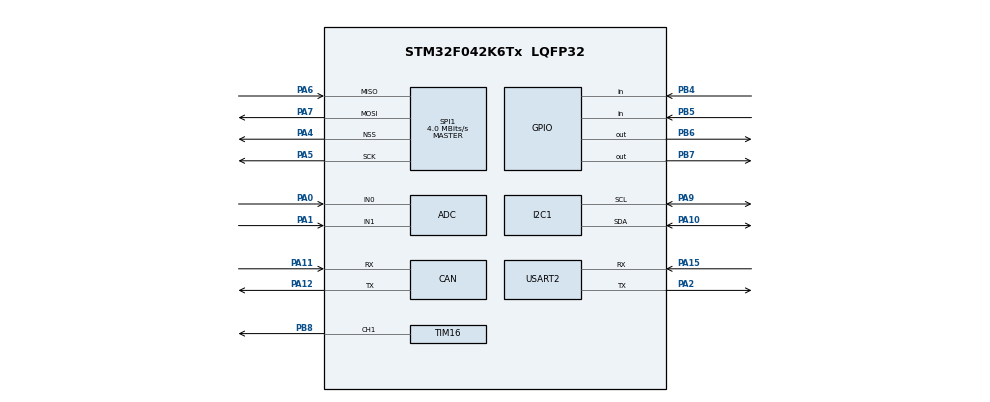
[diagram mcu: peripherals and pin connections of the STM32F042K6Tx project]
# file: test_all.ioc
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CAN.CalculateTimeBit=6000
CAN.CalculateTimeQuantum=2000.0
Mcu.Family=STM32F0
Mcu.Name=STM32F042K6Tx
Mcu.Package=LQFP32
PA0.Mode=IN0
PA0.Signal=ADC_IN0
PA1.Mode=IN1
PA1.Signal=ADC_IN1
PA10.Mode=I2C
PA10.Signal=I2C1_SDA
PA11.Mode=Master
PA11.Signal=CAN_RX
PA12.Mode=Master
PA12.Signal=CAN_TX
PA15.Mode=Asynchronous
PA15.Signal=USART2_RX
PA2.Mode=Asynchronous
PA2.Signal=USART2_TX
PA4.Mode=NSS_Signal_Hard_Output
PA4.Signal=SPI1_NSS
PA5.Mode=Full_Duplex_Master
PA5.Signal=SPI1_SCK
PA6.Mode=Full_Duplex_Master
PA6.Signal=SPI1_MISO
PA7.Mode=Full_Duplex_Master
PA7.Signal=SPI1_MOSI
PA9.Mode=I2C
PA9.Signal=I2C1_SCL
PB4.Signal=GPIO_Input
PB5.Signal=GPIO_Input
PB6.Signal=GPIO_Output
PB7.Signal=GPIO_Output
PB8.Signal=S_TIM16_CH1
ProjectManager.HeapSize=0x200
ProjectManager.StackSize=0x400
ProjectManager.TargetToolchain=Makefile
SH.S_TIM16_CH1.0=TIM16_CH1,PWM Generation1 CH1
SPI1.CalculateBaudRate=4.0 MBits/s
SPI1.Direction=SPI_DIRECTION_2LINES
SPI1.Mode=SPI_MODE_MASTER
SPI1.VirtualNSS=VM_NSSHARD
SPI1.VirtualType=VM_MASTER
TIM16.Channel=TIM_CHANNEL_1
USART2.VirtualMode-Asynchronous=VM_ASYNC
VP_ADC_TempSens_Input.Mode=IN-TempSens
VP_ADC_Vbat_Input.Mode=IN-Vbat
VP_TIM16_VS_ClockSourceINT.Mode=Enable_Timer
board=test_all

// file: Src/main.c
/**
  ******************************************************************************
  * File Name          : main.c
  * Description        : Main program body
  ******************************************************************************
  ** This notice applies to any and all portions of this file
  * that are not between comment pairs USER CODE BEGIN and
  * USER CODE END. Other portions of this file, whether
  * inserted by the user or by software development tools
  * are owned by their respective copyright owners.
  *
  * COPYRIGHT(c) 2017 STMicroelectronics
  *
  * Redistribution and use in source and binary forms, with or without modification,
  * are permitted provided that the following conditions are met:
  *   1. Redistributions of source code must retain the above copyright notice,
  *      this list of conditions and the following disclaimer.
  *   2. Redistributions in binary form must reproduce the above copyright notice,
  *      this list of conditions and the following disclaimer in the documentation
  *      and/or other materials provided with the distribution.
  *   3. Neither the name of STMicroelectronics nor the names of its contributors
  *      may be used to endorse or promote products derived from this software
  *      without specific prior written permission.
  *
  * THIS SOFTWARE IS PROVIDED BY THE COPYRIGHT HOLDERS AND CONTRIBUTORS "AS IS"
  * AND ANY EXPRESS OR IMPLIED WARRANTIES, INCLUDING, BUT NOT LIMITED TO, THE
  * IMPLIED WARRANTIES OF MERCHANTABILITY AND FITNESS FOR A PARTICULAR PURPOSE ARE
  * DISCLAIMED. IN NO EVENT SHALL THE COPYRIGHT HOLDER OR CONTRIBUTORS BE LIABLE
  * FOR ANY DIRECT, INDIRECT, INCIDENTAL, SPECIAL, EXEMPLARY, OR CONSEQUENTIAL
  * DAMAGES (INCLUDING, BUT NOT LIMITED TO, PROCUREMENT OF SUBSTITUTE GOODS OR
  * SERVICES; LOSS OF USE, DATA, OR PROFITS; OR BUSINESS INTERRUPTION) HOWEVER
  * CAUSED AND ON ANY THEORY OF LIABILITY, WHETHER IN CONTRACT, STRICT LIABILITY,
  * OR TORT (INCLUDING NEGLIGENCE OR OTHERWISE) ARISING IN ANY WAY OUT OF THE USE
  * OF THIS SOFTWARE, EVEN IF ADVISED OF THE POSSIBILITY OF SUCH DAMAGE.
  *
  ******************************************************************************
  */

#include "main.h"
#include "stm32f0xx_hal.h"

ADC_HandleTypeDef hadc;

CAN_HandleTypeDef hcan;

I2C_HandleTypeDef hi2c1;

SPI_HandleTypeDef hspi1;

TIM_HandleTypeDef htim16;

UART_HandleTypeDef huart2;

/* USER CODE BEGIN PV */
/* Private variables ---------------------------------------------------------*/

/* USER CODE END PV */

void SystemClock_Config(void);
static void MX_GPIO_Init(void);
static void MX_CAN_Init(void);
static void MX_I2C1_Init(void);
static void MX_ADC_Init(void);
static void MX_SPI1_Init(void);
static void MX_TIM16_Init(void);
static void MX_USART2_UART_Init(void);

void HAL_TIM_MspPostInit(TIM_HandleTypeDef *htim);

/* USER CODE BEGIN PFP */
/* Private function prototypes -----------------------------------------------*/

/* USER CODE END PFP */

/* USER CODE BEGIN 0 */
uint32_t value;
HAL_StatusTypeDef mystatus;
/* USER CODE END 0 */

int main(void)
{

  /* MCU Configuration----------------------------------------------------------*/

  /* Reset of all peripherals, Initializes the Flash interface and the Systick. */
  HAL_Init();

  /* Configure the system clock */
  SystemClock_Config();

  /* Initialize all configured peripherals */
  MX_GPIO_Init();
  MX_CAN_Init();
  MX_I2C1_Init();
  MX_ADC_Init();
  MX_SPI1_Init();
  MX_TIM16_Init();
  MX_USART2_UART_Init();

  //uint8_t mytxbuf = {0xF0, 0xAA}
  uint8_t mytxbuf[] = {'a', 'b', 'c'};
  uint8_t myi2crxbuf[2];

  HAL_UART_Transmit(&huart2, "HI THERE", 8, 500);
  if(myi2crxbuf == NULL) {
  HAL_UART_Transmit(&huart2, "Null", 4, 500);
   }

  //I2C constants
  uint16_t addr = 0x006BU<<1;
  uint16_t reg = 0x000F;
  while (1) {
    myi2crxbuf[0] = 'n';
    mystatus = HAL_I2C_Mem_Read(&hi2c1, addr, reg, 1, myi2crxbuf, 1, 500);
    if (mystatus == HAL_OK) {
      //Status OK, print out the received data
      HAL_UART_Transmit(&huart2, "Stat OK\n\r", 9, 500);
      HAL_UART_Transmit(&huart2, "Rec: ", 5, 500);
      HAL_UART_Transmit(&huart2, myi2crxbuf, 1, 500);
      HAL_UART_Transmit(&huart2, "\r\n", 2, 500);
      HAL_GPIO_TogglePin(GPIOB, GPIO_PIN_3);
    } else if (mystatus == HAL_ERROR) {
      //Error Status, print out the reason
      uint8_t errcode = hi2c1.ErrorCode + '0';
      HAL_UART_Transmit(&huart2, "ERROR_CODE ", 11, 500);
      HAL_UART_Transmit(&huart2, &errcode, 1, 500);
      HAL_UART_Transmit(&huart2, "\r\n", 2, 500);
    } else if (mystatus == HAL_BUSY) {
      HAL_UART_Transmit(&huart2, "Stat BUS\n\r", 10, 500);
    } else if (mystatus == HAL_TIMEOUT) {
      HAL_UART_Transmit(&huart2, "Stat TIM\n\r", 10, 500);
    } else {
      HAL_UART_Transmit(&huart2, "Stat ???\n\r", 10, 500);
    }

    HAL_Delay(500);
    //Set the ADC to read from specific channels in setup for group mode
    //Then call Start, and poll for conversion.  GetValue into a buffer, and read for as many times as channels setup.
    //Call start for next polling round.

    // Start and wait for the conversion
    /*HAL_ADC_Start(&hadc);
    HAL_ADC_PollForConversion(&hadc, 500); //500 msec timeout
    value = HAL_ADC_GetValue(&hadc);
    if (value > (4096/2)) {
      HAL_GPIO_WritePin(GPIOB, GPIO_PIN_3, GPIO_PIN_SET);
    } else {
      HAL_GPIO_WritePin(GPIOB, GPIO_PIN_3, GPIO_PIN_RESET);
    }*/

  }

  /* Now that everything is setup, start the PWM output */
  // HAL_TIM_Base_Start(&htim16);
  // HAL_TIM_PWM_Start(&htim16, TIM_CHANNEL_1);
  // /* Infinite loop */
  // /* USER CODE BEGIN WHILE */
  // uint8_t toggle = 0;

  // while (1) {
  // /* USER CODE END WHILE */
  //   if (toggle) {
  //     __HAL_TIM_SET_COMPARE(&htim16, TIM_CHANNEL_1, 2000);
  //     HAL_GPIO_WritePin(GPIOB, GPIO_PIN_3, GPIO_PIN_SET);
  //   } else {
  //     __HAL_TIM_SET_COMPARE(&htim16, TIM_CHANNEL_1, 4000);
  //     HAL_GPIO_WritePin(GPIOB, GPIO_PIN_3, GPIO_PIN_RESET);

  //   }
  //   toggle ^= 1;
  //   HAL_Delay(500);

  // /* USER CODE BEGIN 3 */

  // }
  /* USER CODE END 3 */

}

/** System Clock Configuration
*/
void SystemClock_Config(void)
{

  RCC_OscInitTypeDef RCC_OscInitStruct;
  RCC_ClkInitTypeDef RCC_ClkInitStruct;
  RCC_PeriphCLKInitTypeDef PeriphClkInit;

    /**Initializes the CPU, AHB and APB busses clocks
    */
  RCC_OscInitStruct.OscillatorType = RCC_OSCILLATORTYPE_HSI|RCC_OSCILLATORTYPE_HSI14;
  RCC_OscInitStruct.HSIState = RCC_HSI_ON;
  RCC_OscInitStruct.HSI14State = RCC_HSI14_ON;
  RCC_OscInitStruct.HSICalibrationValue = 16;
  RCC_OscInitStruct.HSI14CalibrationValue = 16;
  RCC_OscInitStruct.PLL.PLLState = RCC_PLL_NONE;
  if (HAL_RCC_OscConfig(&RCC_OscInitStruct) != HAL_OK)
  {
    _Error_Handler(__FILE__, __LINE__);
  }

    /**Initializes the CPU, AHB and APB busses clocks
    */
  RCC_ClkInitStruct.ClockType = RCC_CLOCKTYPE_HCLK|RCC_CLOCKTYPE_SYSCLK
                              |RCC_CLOCKTYPE_PCLK1;
  RCC_ClkInitStruct.SYSCLKSource = RCC_SYSCLKSOURCE_HSI;
  RCC_ClkInitStruct.AHBCLKDivider = RCC_SYSCLK_DIV1;
  RCC_ClkInitStruct.APB1CLKDivider = RCC_HCLK_DIV1;

  if (HAL_RCC_ClockConfig(&RCC_ClkInitStruct, FLASH_LATENCY_0) != HAL_OK)
  {
    _Error_Handler(__FILE__, __LINE__);
  }

  PeriphClkInit.PeriphClockSelection = RCC_PERIPHCLK_I2C1;
  PeriphClkInit.I2c1ClockSelection = RCC_I2C1CLKSOURCE_HSI;
  if (HAL_RCCEx_PeriphCLKConfig(&PeriphClkInit) != HAL_OK)
  {
    _Error_Handler(__FILE__, __LINE__);
  }

    /**Configure the Systick interrupt time
    */
  HAL_SYSTICK_Config(HAL_RCC_GetHCLKFreq()/1000);

    /**Configure the Systick
    */
  HAL_SYSTICK_CLKSourceConfig(SYSTICK_CLKSOURCE_HCLK);

  /* SysTick_IRQn interrupt configuration */
  HAL_NVIC_SetPriority(SysTick_IRQn, 0, 0);
}

/* ADC init function */
static void MX_ADC_Init(void)
{

  ADC_ChannelConfTypeDef sConfig;

    /**Configure the global features of the ADC (Clock, Resolution, Data Alignment and number of conversion)
    */
  hadc.Instance = ADC1;
  hadc.Init.ClockPrescaler = ADC_CLOCK_ASYNC_DIV1;
  hadc.Init.Resolution = ADC_RESOLUTION_12B;
  hadc.Init.DataAlign = ADC_DATAALIGN_RIGHT;
  //hadc.Init.ScanConvMode = ADC_SCAN_DIRECTION_FORWARD;
  hadc.Init.ScanConvMode = DISABLE;
  //hadc.Init.EOCSelection = ADC_EOC_SINGLE_CONV;
  hadc.Init.EOCSelection = DISABLE;
  hadc.Init.LowPowerAutoWait = DISABLE;
  hadc.Init.LowPowerAutoPowerOff = DISABLE;
  //hadc.Init.ContinuousConvMode = DISABLE;
  hadc.Init.ContinuousConvMode = ENABLE;
  hadc.Init.DiscontinuousConvMode = DISABLE;
  hadc.Init.ExternalTrigConv = ADC_SOFTWARE_START;
  hadc.Init.ExternalTrigConvEdge = ADC_EXTERNALTRIGCONVEDGE_NONE;
  hadc.Init.DMAContinuousRequests = DISABLE;
  hadc.Init.Overrun = ADC_OVR_DATA_PRESERVED;

  if (HAL_ADC_Init(&hadc) != HAL_OK)
  {
    _Error_Handler(__FILE__, __LINE__);
  }

    /**Configure for the selected ADC regular channel to be converted.
    */
  sConfig.Channel = ADC_CHANNEL_0;
  sConfig.Rank = ADC_RANK_CHANNEL_NUMBER;
  sConfig.SamplingTime = ADC_SAMPLETIME_1CYCLE_5;
  if (HAL_ADC_ConfigChannel(&hadc, &sConfig) != HAL_OK)
  {
    _Error_Handler(__FILE__, __LINE__);
  }

    /**Configure for the selected ADC regular channel to be converted.
    */
  // sConfig.Channel = ADC_CHANNEL_1;
  // if (HAL_ADC_ConfigChannel(&hadc, &sConfig) != HAL_OK)
  // {
  //   _Error_Handler(__FILE__, __LINE__);
  // }

    /**Configure for the selected ADC regular channel to be converted.
    */
  // sConfig.Channel = ADC_CHANNEL_2;
  // if (HAL_ADC_ConfigChannel(&hadc, &sConfig) != HAL_OK)
  // {
  //   _Error_Handler(__FILE__, __LINE__);
  // }

    /**Configure for the selected ADC regular channel to be converted.
    */
  // sConfig.Channel = ADC_CHANNEL_TEMPSENSOR;
  // if (HAL_ADC_ConfigChannel(&hadc, &sConfig) != HAL_OK)
  // {
  //   _Error_Handler(__FILE__, __LINE__);
  // }

    /**Configure for the selected ADC regular channel to be converted.
    */
  // sConfig.Channel = ADC_CHANNEL_VBAT;
  // if (HAL_ADC_ConfigChannel(&hadc, &sConfig) != HAL_OK)
  // {
  //   _Error_Handler(__FILE__, __LINE__);
  // }

}

/* CAN init function */
static void MX_CAN_Init(void)
{

  hcan.Instance = CAN;
  hcan.Init.Prescaler = 16;
  hcan.Init.Mode = CAN_MODE_NORMAL;
  hcan.Init.SJW = CAN_SJW_1TQ;
  hcan.Init.BS1 = CAN_BS1_1TQ;
  hcan.Init.BS2 = CAN_BS2_1TQ;
  hcan.Init.TTCM = DISABLE;
  hcan.Init.ABOM = DISABLE;
  hcan.Init.AWUM = DISABLE;
  hcan.Init.NART = DISABLE;
  hcan.Init.RFLM = DISABLE;
  hcan.Init.TXFP = DISABLE;
  if (HAL_CAN_Init(&hcan) != HAL_OK)
  {
    _Error_Handler(__FILE__, __LINE__);
  }

}

/* I2C1 init function */
static void MX_I2C1_Init(void)
{

  hi2c1.Instance = I2C1;
  //hi2c1.Init.Timing = 0x2000090E;
  //hi2c1.Init.Timing = 0x1042C3C7; //Timing for 10kHz clock w/ 8Mhz osc
  //hi2c1.Init.Timing = 0x10420F13;  //Timing for 100kHz clock w/ 8MHz osc
  //hi2c1.Init.Timing = 0x00310309;  //Timing for 400kHz clock w/ 8MHz osc
  hi2c1.Init.Timing = 0x00100306;  //Timing for 500kHz clock w/ 8MHz osc
  hi2c1.Init.OwnAddress1 = 0;
  hi2c1.Init.AddressingMode = I2C_ADDRESSINGMODE_7BIT;
  hi2c1.Init.DualAddressMode = I2C_DUALADDRESS_DISABLE;
  hi2c1.Init.OwnAddress2 = 0;
  hi2c1.Init.OwnAddress2Masks = I2C_OA2_NOMASK;
  hi2c1.Init.GeneralCallMode = I2C_GENERALCALL_DISABLE;
  hi2c1.Init.NoStretchMode = I2C_NOSTRETCH_DISABLE;
  if (HAL_I2C_Init(&hi2c1) != HAL_OK)
  {
    _Error_Handler(__FILE__, __LINE__);
  }

    /**Configure Analogue filter
    */
  if (HAL_I2CEx_ConfigAnalogFilter(&hi2c1, I2C_ANALOGFILTER_ENABLE) != HAL_OK)
  {
    _Error_Handler(__FILE__, __LINE__);
  }

    /**Configure Digital filter
    */
  if (HAL_I2CEx_ConfigDigitalFilter(&hi2c1, 0) != HAL_OK)
  {
    _Error_Handler(__FILE__, __LINE__);
  }

}

/* SPI1 init function */
static void MX_SPI1_Init(void)
{

  /* SPI1 parameter configuration*/
  hspi1.Instance = SPI1;
  hspi1.Init.Mode = SPI_MODE_MASTER;
  hspi1.Init.Direction = SPI_DIRECTION_2LINES;
  hspi1.Init.DataSize = SPI_DATASIZE_4BIT;
  hspi1.Init.CLKPolarity = SPI_POLARITY_LOW;
  hspi1.Init.CLKPhase = SPI_PHASE_1EDGE;
  hspi1.Init.NSS = SPI_NSS_HARD_OUTPUT;
  hspi1.Init.BaudRatePrescaler = SPI_BAUDRATEPRESCALER_2;
  hspi1.Init.FirstBit = SPI_FIRSTBIT_MSB;
  hspi1.Init.TIMode = SPI_TIMODE_DISABLE;
  hspi1.Init.CRCCalculation = SPI_CRCCALCULATION_DISABLE;
  hspi1.Init.CRCPolynomial = 7;
  hspi1.Init.CRCLength = SPI_CRC_LENGTH_DATASIZE;
  hspi1.Init.NSSPMode = SPI_NSS_PULSE_ENABLE;
  if (HAL_SPI_Init(&hspi1) != HAL_OK)
  {
    _Error_Handler(__FILE__, __LINE__);
  }

}

/* TIM16 init function */
static void MX_TIM16_Init(void)
{

  TIM_OC_InitTypeDef sConfigOC;
  TIM_BreakDeadTimeConfigTypeDef sBreakDeadTimeConfig;

  htim16.Instance = TIM16;
  htim16.Init.Prescaler = 0;
  htim16.Init.CounterMode = TIM_COUNTERMODE_UP;
  //htim16.Init.Period = 0;
  htim16.Init.Period = 8000; //TODO Magic number for now
  htim16.Init.ClockDivision = TIM_CLOCKDIVISION_DIV1;
  htim16.Init.RepetitionCounter = 0;
  htim16.Init.AutoReloadPreload = TIM_AUTORELOAD_PRELOAD_DISABLE;
  if (HAL_TIM_Base_Init(&htim16) != HAL_OK)
  {
    _Error_Handler(__FILE__, __LINE__);
  }

  if (HAL_TIM_PWM_Init(&htim16) != HAL_OK)
  {
    _Error_Handler(__FILE__, __LINE__);
  }

  sConfigOC.OCMode = TIM_OCMODE_PWM1;
  sConfigOC.Pulse = 0;
  sConfigOC.OCPolarity = TIM_OCPOLARITY_HIGH;
  sConfigOC.OCNPolarity = TIM_OCNPOLARITY_HIGH;
  sConfigOC.OCFastMode = TIM_OCFAST_DISABLE;
  sConfigOC.OCIdleState = TIM_OCIDLESTATE_RESET;
  sConfigOC.OCNIdleState = TIM_OCNIDLESTATE_RESET;
  if (HAL_TIM_PWM_ConfigChannel(&htim16, &sConfigOC, TIM_CHANNEL_1) != HAL_OK)
  {
    _Error_Handler(__FILE__, __LINE__);
  }

  sBreakDeadTimeConfig.OffStateRunMode = TIM_OSSR_DISABLE;
  sBreakDeadTimeConfig.OffStateIDLEMode = TIM_OSSI_DISABLE;
  sBreakDeadTimeConfig.LockLevel = TIM_LOCKLEVEL_OFF;
  sBreakDeadTimeConfig.DeadTime = 0;
  sBreakDeadTimeConfig.BreakState = TIM_BREAK_DISABLE;
  sBreakDeadTimeConfig.BreakPolarity = TIM_BREAKPOLARITY_HIGH;
  sBreakDeadTimeConfig.AutomaticOutput = TIM_AUTOMATICOUTPUT_DISABLE;
  if (HAL_TIMEx_ConfigBreakDeadTime(&htim16, &sBreakDeadTimeConfig) != HAL_OK)
  {
    _Error_Handler(__FILE__, __LINE__);
  }

  HAL_TIM_MspPostInit(&htim16);

}

/* USART2 init function */
static void MX_USART2_UART_Init(void)
{

  huart2.Instance = USART2;
  huart2.Init.BaudRate = 38400;
  huart2.Init.StopBits = UART_STOPBITS_1;
  huart2.Init.Parity = UART_PARITY_NONE;
  huart2.Init.WordLength = UART_WORDLENGTH_8B;
  huart2.Init.Mode = UART_MODE_TX_RX;
  huart2.Init.HwFlowCtl = UART_HWCONTROL_NONE;
  huart2.Init.OverSampling = UART_OVERSAMPLING_16;
  huart2.Init.OneBitSampling = UART_ONE_BIT_SAMPLE_DISABLE;
  huart2.AdvancedInit.AdvFeatureInit = UART_ADVFEATURE_NO_INIT;
  if (HAL_UART_Init(&huart2) != HAL_OK)
  {
    _Error_Handler(__FILE__, __LINE__);
  }

}

/** Configure pins as
        * Analog
        * Input
        * Output
        * EVENT_OUT
        * EXTI
*/
static void MX_GPIO_Init(void)
{

  GPIO_InitTypeDef GPIO_InitStruct;

  /* GPIO Ports Clock Enable */
  __HAL_RCC_GPIOF_CLK_ENABLE();
  __HAL_RCC_GPIOA_CLK_ENABLE();
  __HAL_RCC_GPIOB_CLK_ENABLE();

  /*Configure GPIO pin Output Level */
  HAL_GPIO_WritePin(GPIOB, GPIO_PIN_6|GPIO_PIN_7|GPIO_PIN_3, GPIO_PIN_RESET); //Add the LED
  //HAL_GPIO_WritePin(GPIOB, GPIO_PIN_6|GPIO_PIN_7, GPIO_PIN_RESET);

  /*Configure GPIO pins : PB4 PB5 */
  GPIO_InitStruct.Pin = GPIO_PIN_4|GPIO_PIN_5;
  GPIO_InitStruct.Mode = GPIO_MODE_INPUT;
  GPIO_InitStruct.Pull = GPIO_NOPULL;
  HAL_GPIO_Init(GPIOB, &GPIO_InitStruct);

  /*Configure GPIO pins : PB6 PB7 */
  GPIO_InitStruct.Pin = GPIO_PIN_6|GPIO_PIN_7|GPIO_PIN_3; //Add the LED
  //GPIO_InitStruct.Pin = GPIO_PIN_6|GPIO_PIN_7;
  GPIO_InitStruct.Mode = GPIO_MODE_OUTPUT_PP;
  GPIO_InitStruct.Pull = GPIO_NOPULL;
  GPIO_InitStruct.Speed = GPIO_SPEED_FREQ_LOW;
  HAL_GPIO_Init(GPIOB, &GPIO_InitStruct);

}

void _Error_Handler(char * file, int line)
{
  while(1)
  {
  }
}

/************************ (C) COPYRIGHT STMicroelectronics *****END OF FILE****/
